VERSION "1.0"

NS_ :

BS_:

BU_: ECU1 ECU2 ECU3

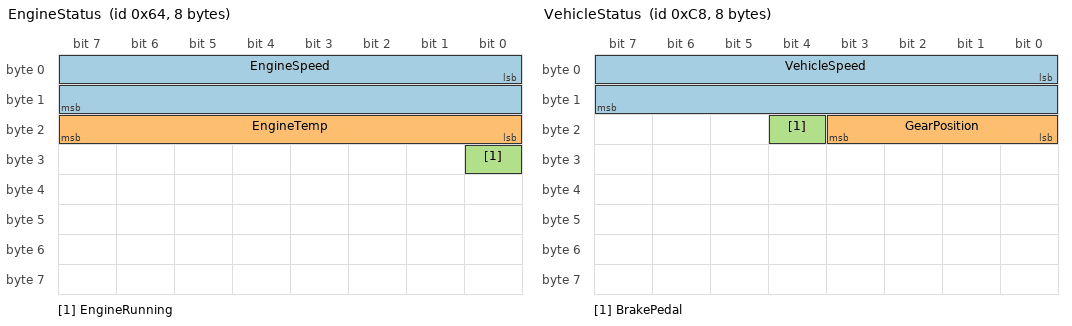
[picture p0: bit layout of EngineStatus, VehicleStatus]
BO_ 100 EngineStatus: 8 ECU1
 SG_ EngineSpeed : 0|16@1+ (0.1,0) [0|6500] "rpm" ECU2,ECU3
 SG_ EngineTemp : 16|8@1+ (1,-40) [-40|215] "C" ECU2
 SG_ EngineRunning : 24|1@1+ (1,0) [0|1] "" ECU2,ECU3

BO_ 200 VehicleStatus: 8 ECU2
 SG_ VehicleSpeed : 0|16@1+ (0.01,0) [0|250] "km/h" ECU1,ECU3
 SG_ GearPosition : 16|4@1+ (1,0) [0|10] "" ECU1
 SG_ BrakePedal : 20|1@1+ (1,0) [0|1] "" ECU1,ECU3

CM_ BO_ 100 "Engine status message";
CM_ SG_ 100 EngineSpeed "Engine speed in RPM";
CM_ SG_ 100 EngineTemp "Engine temperature";
CM_ SG_ 100 EngineRunning "0=Off, 1=Running";

CM_ BO_ 200 "Overall vehicle status";
CM_ SG_ 200 VehicleSpeed "Vehicle speed";
CM_ SG_ 200 GearPosition "Current gear: 0=Neutral, 1-6=Forward gears, 7=Reverse";
CM_ SG_ 200 BrakePedal "Brake pedal status: 0=Released, 1=Pressed";

BA_DEF_ BO_ "GenMsgCycleTime" INT 0 65535;

BA_ "GenMsgCycleTime" BO_ 100 100;
BA_ "GenMsgCycleTime" BO_ 200 200;

VAL_ 200 GearPosition 0 "Neutral" 1 "First" 2 "Second" 3 "Third" 4 "Fourth" 5 "Fifth" 6 "Sixth" 7 "Reverse";
